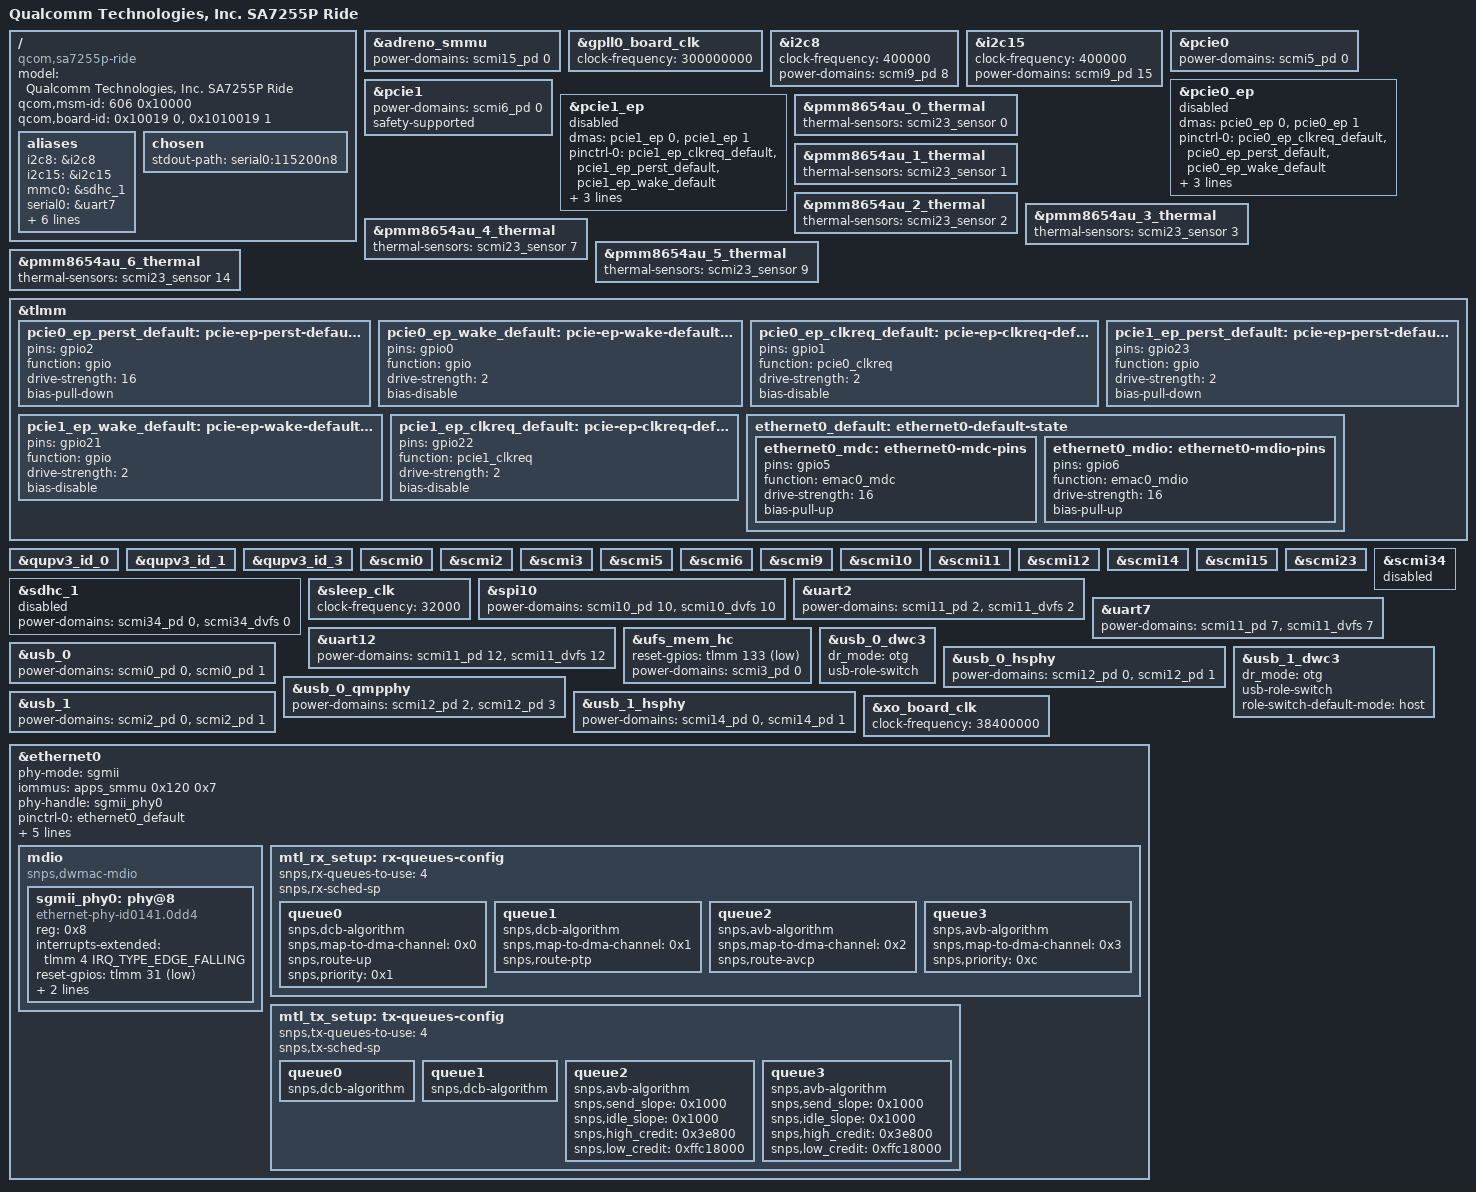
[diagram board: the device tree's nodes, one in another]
// SPDX-License-Identifier: BSD-3-Clause
/*
 * Copyright (c) Qualcomm Technologies, Inc. and/or its subsidiaries.
 */

/dts-v1/;

#include <dt-bindings/gpio/gpio.h>

#include "sa7255p.dtsi"
#include "sa7255p-scmi.dtsi"
#include "sa7255p-pmics.dtsi"

/ {
	model = "Qualcomm Technologies, Inc. SA7255P Ride";
	compatible = "qcom,sa7255p-ride","qcom,sa7255p";
	qcom,msm-id = <606 0x10000>;
	qcom,board-id = <0x10019 0>, <0x1010019 1>;

	aliases {
		i2c8 = &i2c8;
		i2c15 = &i2c15;
		mmc0 = &sdhc_1;
		serial0 = &uart7;
		serial1 = &uart12;
		serial2 = &uart2;
		spi10 = &spi10;
		scmichannels = &scmichannels;
		ufshc1 = &ufs_mem_hc;
		ethernet0 = &ethernet0;
	};

	chosen {
		stdout-path = "serial0:115200n8";
	};
};

&adreno_smmu {
	power-domains = <&scmi15_pd 0>;

	status = "okay";
};

&gpll0_board_clk {
	clock-frequency = <300000000>;
};

&i2c8 {
	clock-frequency = <400000>;
	power-domains = <&scmi9_pd 8>;

	status = "okay";
};

&i2c15 {
	clock-frequency = <400000>;
	power-domains = <&scmi9_pd 15>;

	status = "okay";
};

&pcie0 {
	power-domains = <&scmi5_pd 0>;
	power-domain-names = "power";
	status = "okay";
};

&pcie1 {
	power-domains = <&scmi6_pd 0>;
	power-domain-names = "power";
	safety-supported;
	status = "okay";
};

&pcie0_ep {
	#dma-cells = <1>;
	dmas = <&pcie0_ep 0>, <&pcie0_ep 1>;
	dma-names = "rx", "tx";

	pinctrl-names = "default";
	pinctrl-0 = <&pcie0_ep_clkreq_default &pcie0_ep_perst_default
		    &pcie0_ep_wake_default>;

	reset-gpio = <&tlmm 2 GPIO_ACTIVE_LOW>;
	wake-gpios = <&tlmm 0 GPIO_ACTIVE_HIGH>;

	power-domains = <&scmi5_pd 1>;
	power-domain-names = "power";

	status = "disabled";
};

&pcie1_ep {
	#dma-cells = <1>;
	dmas = <&pcie1_ep 0>, <&pcie1_ep 1>;
	dma-names = "rx", "tx";

	pinctrl-names = "default";
	pinctrl-0 = <&pcie1_ep_clkreq_default &pcie1_ep_perst_default
		    &pcie1_ep_wake_default>;

	reset-gpio = <&tlmm 23 GPIO_ACTIVE_LOW>;
	wake-gpios = <&tlmm 21 GPIO_ACTIVE_HIGH>;

	power-domains = <&scmi6_pd 1>;
	power-domain-names = "power";

	status = "disabled";
};

&pmm8654au_0_thermal {
	thermal-sensors = <&scmi23_sensor 0>;
};

&pmm8654au_1_thermal {
	thermal-sensors = <&scmi23_sensor 1>;
};

&pmm8654au_2_thermal {
	thermal-sensors = <&scmi23_sensor 2>;
};

&pmm8654au_3_thermal {
	thermal-sensors = <&scmi23_sensor 3>;
};

&pmm8654au_4_thermal {
	thermal-sensors = <&scmi23_sensor 7>;
};

&pmm8654au_5_thermal {
	thermal-sensors = <&scmi23_sensor 9>;
};

&pmm8654au_6_thermal {
	thermal-sensors = <&scmi23_sensor 14>;
};

&tlmm {
		pcie0_ep_perst_default: pcie-ep-perst-default-state {
			pins = "gpio2";
			function = "gpio";
			drive-strength = <16>;
			bias-pull-down;
		};

		pcie0_ep_wake_default: pcie-ep-wake-default-state {
			pins = "gpio0";
			function = "gpio";
			drive-strength = <2>;
			bias-disable;
		};

		pcie0_ep_clkreq_default: pcie-ep-clkreq-default-state {
			pins = "gpio1";
			function = "pcie0_clkreq";
			drive-strength = <2>;
			bias-disable;
		};

		pcie1_ep_perst_default: pcie-ep-perst-default-state {
			pins = "gpio23";
			function = "gpio";
			drive-strength = <2>;
			bias-pull-down;
		};

		pcie1_ep_wake_default: pcie-ep-wake-default-state {
			pins = "gpio21";
			function = "gpio";
			drive-strength = <2>;
			bias-disable;
		};

		pcie1_ep_clkreq_default: pcie-ep-clkreq-default-state {
			pins = "gpio22";
			function = "pcie1_clkreq";
			drive-strength = <2>;
			bias-disable;
		};
};

&qupv3_id_0 {
	status = "okay";
};

&qupv3_id_1 {
	status = "okay";
};

&qupv3_id_3 {
	status = "okay";
};

&scmi0 {
	status = "okay";
};

&scmi2 {
	status = "okay";
};

&scmi3 {
	status = "okay";
};

&scmi5 {
	status = "okay";
};

&scmi6 {
	status = "okay";
};

&scmi9 {
	status = "okay";
};

&scmi10 {
	status = "okay";
};

&scmi11 {
	status = "okay";
};

&scmi12 {
	status = "okay";
};

&scmi14 {
	status = "okay";
};

&scmi15 {
	status = "okay";
};

&scmi23 {
	status = "okay";
};

&scmi34 {
	status = "disabled";
};

&sdhc_1 {
	power-domains = <&scmi34_pd 0>, <&scmi34_dvfs 0>;
	power-domain-names = "power", "perf";

	status = "disabled";
};

&sleep_clk {
	clock-frequency = <32000>;
};

&spi10 {
	power-domains = <&scmi10_pd 10>, <&scmi10_dvfs 10>;
	power-domain-names = "power", "perf";

	status = "okay";
};

&uart2 {
	power-domains = <&scmi11_pd 2>, <&scmi11_dvfs 2>;
	power-domain-names = "power", "perf";

	status = "okay";
};

&uart7 {
	power-domains = <&scmi11_pd 7>, <&scmi11_dvfs 7>;
	power-domain-names = "power", "perf";

	status = "okay";
};

&uart12 {
	power-domains = <&scmi11_pd 12>, <&scmi11_dvfs 12>;
	power-domain-names = "power", "perf";

	status = "okay";
};

&ufs_mem_hc {
	reset-gpios = <&tlmm 133 GPIO_ACTIVE_LOW>;
	power-domains = <&scmi3_pd 0>;

	status = "okay";
};

&usb_0 {
	power-domains = <&scmi0_pd 0>, <&scmi0_pd 1>;
	power-domain-names = "usb_transfer", "usb_core";

	status = "okay";
};

&usb_0_dwc3 {
	dr_mode = "otg";
	usb-role-switch;
};

&usb_0_hsphy {
	power-domains = <&scmi12_pd 0>, <&scmi12_pd 1>;
	power-domain-names = "usb_transfer", "usb_core";

	status = "okay";
};

&usb_0_qmpphy {
	power-domains = <&scmi12_pd 2>, <&scmi12_pd 3>;
	power-domain-names = "usb_transfer", "usb_core";

	status = "okay";
};

&usb_1 {
	power-domains = <&scmi2_pd 0>, <&scmi2_pd 1>;
	power-domain-names = "usb_transfer", "usb_core";

	status = "okay";
};

&usb_1_dwc3 {
	dr_mode = "otg";
	usb-role-switch;
	role-switch-default-mode = "host";
};

&usb_1_hsphy {
	power-domains = <&scmi14_pd 0>, <&scmi14_pd 1>;
	power-domain-names = "usb_transfer", "usb_core";

	status = "okay";
};

&xo_board_clk {
	clock-frequency = <38400000>;
};

&ethernet0 {
	phy-mode = "sgmii";
	iommus = <&apps_smmu 0x120 0x7>;
	phy-handle = <&sgmii_phy0>;

	pinctrl-names = "default";
	pinctrl-0 = <&ethernet0_default>;

	snps,mtl-rx-config = <&mtl_rx_setup>;
	snps,mtl-tx-config = <&mtl_tx_setup>;
	snps,ps-speed = <1000>;

	power-domains = <&scmi7_pd 0>, <&scmi7_pd 1>, <&scmi7_dvfs 0>;
	power-domain-names = "power_core", "power_mdio", "perf_serdes";

	status = "okay";

	mdio {
		compatible = "snps,dwmac-mdio";
		#address-cells = <1>;
		#size-cells = <0>;

		sgmii_phy0: phy@8 {
			compatible = "ethernet-phy-id0141.0dd4";
			reg = <0x8>;
			device_type = "ethernet-phy";
			interrupts-extended = <&tlmm 4 IRQ_TYPE_EDGE_FALLING>;
			reset-gpios = <&tlmm 31 GPIO_ACTIVE_LOW>;
			reset-assert-us = <11000>;
			reset-deassert-us = <70000>;
		};
	};

	mtl_rx_setup: rx-queues-config {
		snps,rx-queues-to-use = <4>;
		snps,rx-sched-sp;

		queue0 {
			snps,dcb-algorithm;
			snps,map-to-dma-channel = <0x0>;
			snps,route-up;
			snps,priority = <0x1>;
		};

		queue1 {
			snps,dcb-algorithm;
			snps,map-to-dma-channel = <0x1>;
			snps,route-ptp;
		};

		queue2 {
			snps,avb-algorithm;
			snps,map-to-dma-channel = <0x2>;
			snps,route-avcp;
		};

		queue3 {
			snps,avb-algorithm;
			snps,map-to-dma-channel = <0x3>;
			snps,priority = <0xc>;
		};
	};

	mtl_tx_setup: tx-queues-config {
		snps,tx-queues-to-use = <4>;
		snps,tx-sched-sp;

		queue0 {
			snps,dcb-algorithm;
		};

		queue1 {
			snps,dcb-algorithm;
		};

		queue2 {
			snps,avb-algorithm;
			snps,send_slope = <0x1000>;
			snps,idle_slope = <0x1000>;
			snps,high_credit = <0x3e800>;
			snps,low_credit = <0xffc18000>;
		};

		queue3 {
			snps,avb-algorithm;
			snps,send_slope = <0x1000>;
			snps,idle_slope = <0x1000>;
			snps,high_credit = <0x3e800>;
			snps,low_credit = <0xffc18000>;
		};
	};
};

&tlmm {
	ethernet0_default: ethernet0-default-state {
		ethernet0_mdc: ethernet0-mdc-pins {
			pins = "gpio5";
			function = "emac0_mdc";
			drive-strength = <16>;
			bias-pull-up;
		};

		ethernet0_mdio: ethernet0-mdio-pins {
			pins = "gpio6";
			function = "emac0_mdio";
			drive-strength = <16>;
			bias-pull-up;
		};
	};
};
